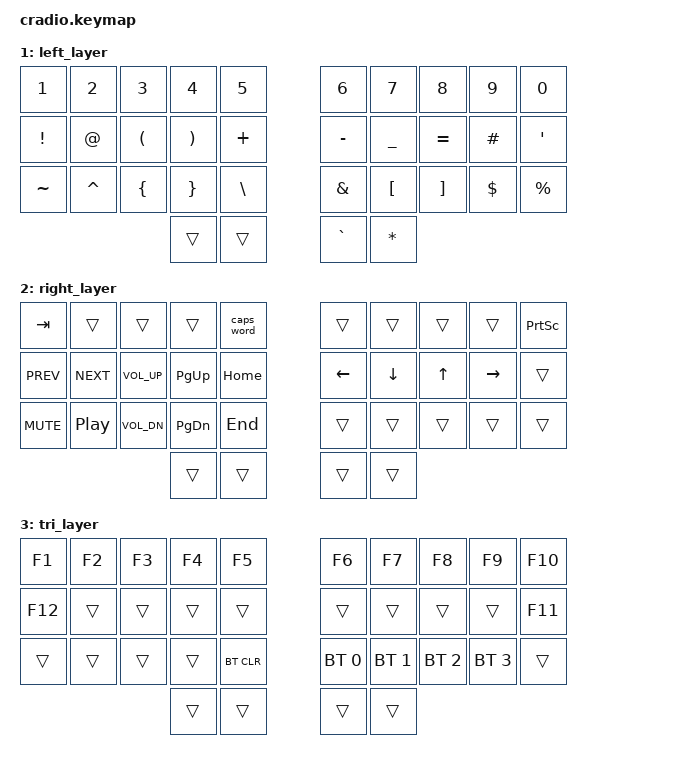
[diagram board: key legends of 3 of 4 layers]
// Copyright (c) 2022 The ZMK Contributors
// SPDX-License-Identifier: MIT

#include <behaviors.dtsi>
#include <dt-bindings/zmk/keys.h>
#include <dt-bindings/zmk/bt.h>

// Home row mods macro
#define HRML(k1,k2,k3,k4) &ht LSHFT k1  &ht LALT k2  &ht LCTRL k3  &ht LGUI k4
#define HRMR(k1,k2,k3,k4) &ht RGUI k1  &ht RCTRL k2  &ht RALT k3  &ht RSHFT k4

/ {
    behaviors {
        ht: hold_tap {
            label = "hold_tap";
            compatible = "zmk,behavior-hold-tap";
            #binding-cells = <2>;
            flavor = "tap-preferred";
            tapping-term-ms = <220>;
            quick-tap-ms = <150>;
            global-quick-tap;
            bindings = <&kp>, <&kp>;
        };
    };

    conditional_layers {
        compatible = "zmk,conditional-layers";
        tri_layer {
            if-layers = <1 2>;
            then-layer = <3>;
        };
    };

    keymap {
        compatible = "zmk,keymap";
        default_layer {
            bindings = <
        //╭──────────┬──────────┬──────────┬──────────┬──────────╮   ╭──────────┬──────────┬──────────┬──────────┬──────────╮
        //│  Q       │  W       │  E       │  R       │  T       │   │  Y       │  U       │  I       │  O       │ P        │
            &kp Q      &kp W      &kp E      &kp R      &kp T          &kp Y      &kp U      &kp I      &kp O      &kp P
        //├──────────┼──────────┼──────────┼──────────┼──────────┤   ├──────────┼──────────┼──────────┼──────────┼──────────┤
        //│  A       │  S       │  D       │  F       │  G       │   │  H       │  J       │  K       │  L       │  ;       │
            HRML(A,        S,         D,         F)     &kp G          &kp H      HRMR(J,        K,         L,        SEMI)
        //├──────────┼──────────┼──────────┼──────────┼──────────┤   ├──────────┼──────────┼──────────┼──────────┼──────────┤
        //│  Z       │  X       │  C       │  V       │  B       │   │  N       │  M       │ , <      │ . >      │ / ?      │
            &kp Z      &kp X      &kp C      &kp V      &kp B          &kp N      &kp M      &kp COMMA  &kp DOT    &kp FSLH
        //╰──────────┴──────────┴──────────┼──────────┼──────────┤   ├──────────┼──────────┼──────────┴──────────┴──────────╯
                                            &lt 1 ESC   &kp SPACE     &kp ENTER  &lt 2 BSPC
        //                                 ╰──────────┴──────────╯   ╰──────────┴──────────╯
            >;
        };

        left_layer {
            bindings = <
        //╭──────────┬──────────┬──────────┬──────────┬──────────╮   ╭──────────┬──────────┬──────────┬──────────┬──────────╮
        //│  1       │  2       │  3       │  4       │  5       │   │  6       │  7       │  8       │  9       │  0       │
            &kp N1     &kp N2     &kp N3     &kp N4     &kp N5         &kp N6     &kp N7     &kp N8     &kp N9     &kp N0
        //├──────────┼──────────┼──────────┼──────────┼──────────┤   ├──────────┼──────────┼──────────┼──────────┼──────────┤
        //│  !       │  @       │  (       │  )       │  +       │   │  -       │  _       │  =       │  #       │  sqt     │
            &kp EXCL   &kp AT     &kp LPAR   &kp RPAR   &kp PLUS       &kp MINUS  &kp UNDER  &kp EQUAL  &kp HASH   &kp SQT
        //├──────────┼──────────┼──────────┼──────────┼──────────┤   ├──────────┼──────────┼──────────┼──────────┼──────────┤
        //│  ~       │  ^       │  {       │  }       │  \ |     │   │  &       │  [       │  ]       │  $       │  %       │
            &kp TILDE   &kp CARET   &kp LBRC   &kp RBRC   &kp BSLH      &kp AMPS   &kp LBKT   &kp RBKT   &kp DLLR  &kp PRCNT
        //╰──────────┴──────────┴──────────┼──────────┼──────────┤   ├──────────┼──────────┼──────────┴──────────┴──────────╯
                                             &trans     &trans        &kp GRAVE   &kp STAR
        //                                 ╰──────────┴──────────╯   ╰────`─────┴──────────╯
            >;
        };

        right_layer {
            bindings = <
        //╭──────────┬──────────┬──────────┬──────────┬──────────╮   ╭──────────┬──────────┬──────────┬──────────┬──────────╮
        //│  TAB     │          │          │          │  CAPS    │   │          │          │          │          │  PSCRN   │
            &kp TAB    &trans     &trans     &trans    &caps_word      &trans     &trans     &trans     &trans    &kp PSCRN
        //├──────────┼──────────┼──────────┼──────────┼──────────┤   ├──────────┼──────────┼──────────┼──────────┼──────────┤
        //│  PREV    │  NEXT    │ VOL UP   │  PG UP   │  HOME    │   │  LEFT    │  DOWN    │  UP      │  RIGHT   │          │
         &kp C_PREV  &kp C_NEXT &kp C_VOL_UP  &kp PG_UP &kp HOME       &kp LEFT   &kp DOWN   &kp UP    &kp RIGHT   &trans
        //├──────────┼──────────┼──────────┼──────────┼──────────┤   ├──────────┼──────────┼──────────┼──────────┼──────────┤
        //│  MUTE    │  P/P     │ VOL DOWN │  PG DOWN │  END     │   │          │          │          │          │          │
           &kp C_MUTE &kp C_PP  &kp C_VOL_DN &kp PG_DN  &kp END        &trans     &trans     &trans     &trans     &trans
        //╰──────────┴──────────┴──────────┼──────────┼──────────┤   ├──────────┼──────────┼──────────┴──────────┴──────────╯
                                             &trans     &trans         &trans     &trans
        //                                 ╰──────────┴──────────╯   ╰──────────┴──────────
            >;
        };

        tri_layer {
            bindings = <
        //╭──────────┬──────────┬──────────┬──────────┬──────────╮   ╭──────────┬──────────┬──────────┬──────────┬──────────╮
        //│  F1      │  F2      │  F3      │  F4      │  F5      │   │  F6      │  F7      │  F8      │  F9      │  F10     │
            &kp F1     &kp F2     &kp F3     &kp F4     &kp F5         &kp F6     &kp F7     &kp F8     &kp F9     &kp F10
        //├──────────┼──────────┼──────────┼──────────┼──────────┤   ├──────────┼──────────┼──────────┼──────────┼──────────┤
        //│  F12     │          │          │          │          │   │          │          │          │          │  F11     │
            &kp F12    &trans     &trans     &trans    &trans          &trans     &trans     &trans     &trans     &kp F11
        //├──────────┼──────────┼──────────┼──────────┼──────────┤   ├──────────┼──────────┼──────────┼──────────┼──────────┤
        //│          │          │          │          │ CLEAR BT │   │PROFILE 0 │PROFILE 1 │PROFILE 2 │PROFILE 3 │          │
            &trans     &trans     &trans     &trans    &bt BT_CLR   &bt BT_SEL 0  &bt BT_SEL 1 &bt BT_SEL 2 &bt BT_SEL 3   &trans
        //╰──────────┴──────────┴──────────┼──────────┼──────────┤   ├──────────┼──────────┼──────────┴──────────┴──────────╯
                                             &trans     &trans         &trans     &trans
        //                                 ╰──────────┴──────────╯   ╰──────────┴──────────╯
            >;
        };
        
    };
};
